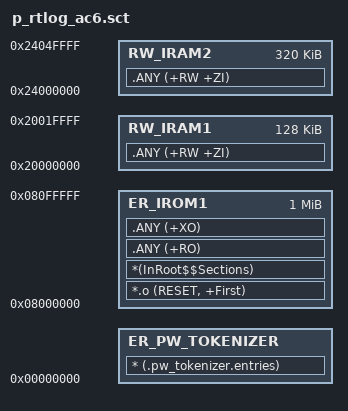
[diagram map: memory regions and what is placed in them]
; *************************************************************
; *** Stable Scatter-Loading Description for P-RTLog + AC6  ***
; *************************************************************
;
; This file lives outside the generated output directory so it will not be
; overwritten by rebuilds or project regeneration.
;
; Tokenizer metadata: keep in AXF for host-side decode, do not place in flash image.
LR_PW_TOKENIZER 0x00000000 {
  ER_PW_TOKENIZER 0x00000000 {
   * (.pw_tokenizer.entries)
  }
}

; Main image regions
LR_IROM1 0x08000000 0x00100000  {
  ER_IROM1 0x08000000 0x00100000  {
   *.o (RESET, +First)
   *(InRoot$$Sections)
   .ANY (+RO)
   .ANY (+XO)
  }
  RW_IRAM1 0x20000000 0x00020000  {
   .ANY (+RW +ZI)
  }
  RW_IRAM2 0x24000000 0x00050000  {
   .ANY (+RW +ZI)
  }
}
